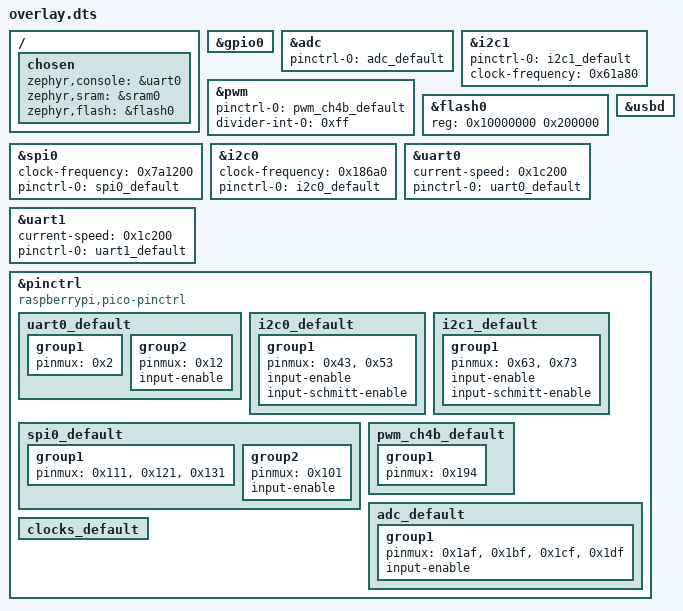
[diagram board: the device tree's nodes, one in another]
/ {
	chosen {
		zephyr,console = &uart0;
		zephyr,sram = &sram0;
		zephyr,flash = &flash0;
	};
};
&gpio0{
	status = "okay";
};
&adc{
	status = "okay";
	pinctrl-0 = < &adc_default >;
	pinctrl-names = "default";
};
&i2c1{
	pinctrl-0 = < &i2c1_default >;
	pinctrl-names = "default";
	clock-frequency = < 0x61a80 >;
};
&pwm{
	pinctrl-0 = < &pwm_ch4b_default >;
	pinctrl-names = "default";
	divider-int-0 = < 0xff >;
};
&flash0{
	reg = < 0x10000000 0x200000 >;
};
&spi0{
	status = "okay";
	clock-frequency = < 0x7a1200 >;
	pinctrl-0 = < &spi0_default >;
	pinctrl-names = "default";
};
&i2c0{
	status = "okay";
	clock-frequency = < 0x186a0 >;
	pinctrl-0 = < &i2c0_default >;
	pinctrl-names = "default";
};
&uart0{
	status = "okay";
	current-speed = < 0x1c200 >;
	pinctrl-0 = < &uart0_default >;
	pinctrl-names = "default";
};
&usbd{
	status = "okay";
};
&uart1{
	status = "okay";
	current-speed = < 0x1c200 >;
	pinctrl-0 = < &uart1_default >;
	pinctrl-names = "default";
};
&pinctrl{
	compatible = "raspberrypi,pico-pinctrl";
	uart0_default: uart0_default {
		group1 {
			pinmux = < 0x2 >;
		};
		group2 {
			pinmux = < 0x12 >;
			input-enable;
		};
	};
	i2c0_default: i2c0_default {
		group1 {
			pinmux = < 0x43 >, < 0x53 >;
			input-enable;
			input-schmitt-enable;
		};
	};
	i2c1_default: i2c1_default {
		group1 {
			pinmux = < 0x63 >, < 0x73 >;
			input-enable;
			input-schmitt-enable;
		};
	};
	spi0_default: spi0_default {
		group1 {
			pinmux = < 0x111 >, < 0x121 >, < 0x131 >;
		};
		group2 {
			pinmux = < 0x101 >;
			input-enable;
		};
	};
	pwm_ch4b_default: pwm_ch4b_default {
		group1 {
			pinmux = < 0x194 >;
		};
	};
	adc_default: adc_default {
		group1 {
			pinmux = < 0x1af >, < 0x1bf >, < 0x1cf >, < 0x1df >;
			input-enable;
		};
	};
	clocks_default: clocks_default {
	};
};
